AUTOSAR XML (schema 4-0-3)
package /ComponentTypes
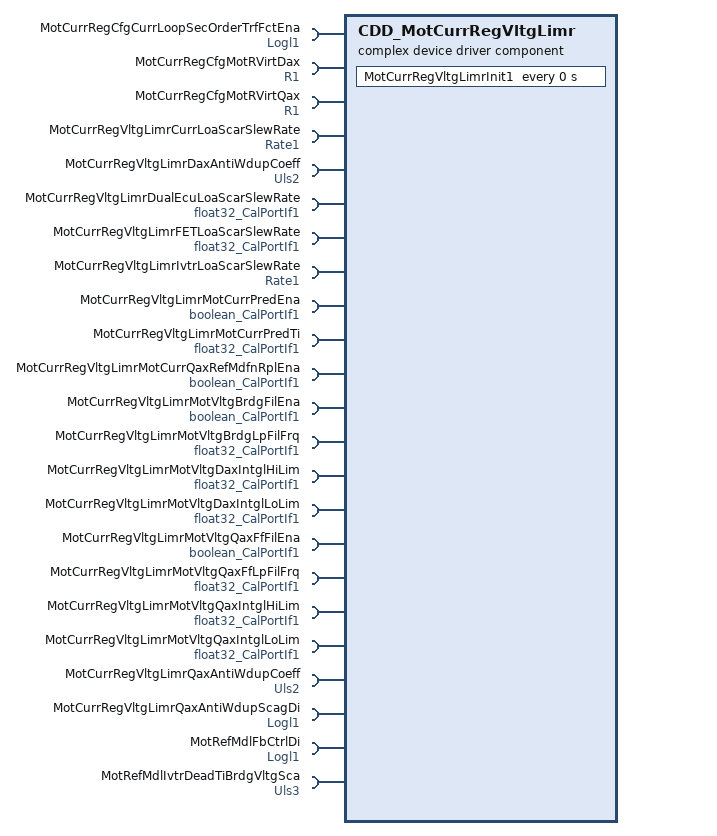
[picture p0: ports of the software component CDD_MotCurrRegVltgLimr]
  complex device driver sw component type CDD_MotCurrRegVltgLimr
    23 x require port:
      MotCurrRegCfgCurrLoopSecOrderTrfFctEna: parameter-require-com-spec{init-value=1, parameter=Logl}, required-interface=Logl1
      MotCurrRegCfgMotRVirtDax: parameter-require-com-spec{init-value=0, parameter=Val}, required-interface=R1
      MotCurrRegCfgMotRVirtQax: parameter-require-com-spec{init-value=0, parameter=Val}, required-interface=R1
      MotCurrRegVltgLimrCurrLoaScarSlewRate: parameter-require-com-spec{init-value=100, parameter=Val}, required-interface=Rate1
      MotCurrRegVltgLimrDaxAntiWdupCoeff: parameter-require-com-spec{init-value=0, parameter=Val}, required-interface=Uls2
      MotCurrRegVltgLimrDualEcuLoaScarSlewRate: parameter-require-com-spec{init-value=100, parameter=Val}, required-interface=float32_CalPortIf1
      MotCurrRegVltgLimrFETLoaScarSlewRate: parameter-require-com-spec{init-value=100, parameter=Val}, required-interface=float32_CalPortIf1
      MotCurrRegVltgLimrIvtrLoaScarSlewRate: parameter-require-com-spec{init-value=100, parameter=Val}, required-interface=Rate1
      MotCurrRegVltgLimrMotCurrPredEna: parameter-require-com-spec{init-value=0, parameter=Logl}, required-interface=boolean_CalPortIf1
      MotCurrRegVltgLimrMotCurrPredTi: parameter-require-com-spec{init-value=0, parameter=Val}, required-interface=float32_CalPortIf1
      MotCurrRegVltgLimrMotCurrQaxRefMdfnRplEna: parameter-require-com-spec{init-value=0, parameter=Logl}, required-interface=boolean_CalPortIf1
      MotCurrRegVltgLimrMotVltgBrdgFilEna: parameter-require-com-spec{init-value=1, parameter=Logl}, required-interface=boolean_CalPortIf1
      MotCurrRegVltgLimrMotVltgBrdgLpFilFrq: parameter-require-com-spec{init-value=200, parameter=Val}, required-interface=float32_CalPortIf1
      MotCurrRegVltgLimrMotVltgDaxIntglHiLim: parameter-require-com-spec{init-value=9, parameter=Val}, required-interface=float32_CalPortIf1
      MotCurrRegVltgLimrMotVltgDaxIntglLoLim: parameter-require-com-spec{init-value=-4.5, parameter=Val}, required-interface=float32_CalPortIf1
      MotCurrRegVltgLimrMotVltgQaxFfFilEna: parameter-require-com-spec{init-value=1, parameter=Logl}, required-interface=boolean_CalPortIf1
      MotCurrRegVltgLimrMotVltgQaxFfLpFilFrq: parameter-require-com-spec{init-value=500, parameter=Val}, required-interface=float32_CalPortIf1
      MotCurrRegVltgLimrMotVltgQaxIntglHiLim: parameter-require-com-spec{init-value=14.5, parameter=Val}, required-interface=float32_CalPortIf1
      MotCurrRegVltgLimrMotVltgQaxIntglLoLim: parameter-require-com-spec{init-value=-14.5, parameter=Val}, required-interface=float32_CalPortIf1
      MotCurrRegVltgLimrQaxAntiWdupCoeff: parameter-require-com-spec{init-value=0, parameter=Val}, required-interface=Uls2
      MotCurrRegVltgLimrQaxAntiWdupScagDi: parameter-require-com-spec{init-value=0, parameter=Logl}, required-interface=Logl1
      MotRefMdlFbCtrlDi: parameter-require-com-spec{init-value=0, parameter=Logl}, required-interface=Logl1
      MotRefMdlIvtrDeadTiBrdgVltgSca: parameter-require-com-spec{init-value=1, parameter=Val}, required-interface=Uls3
    behavior CDD_MotCurrRegVltgLimr_InternalBehavior: data-type-mapping=Nexteer
      ar-typed-per-instance-memorys:
        39 x data, all with sw-calibration-access=READ-ONLY:
          AntiWdupCmdScaDax: type=Uls2
          AntiWdupCmdScaQax: type=Uls2
          CurrLoaScarPrev: type=Uls2
          dMotCurrRegVltgLimrAntiWdupCmdScaDax: type=Uls2
          dMotCurrRegVltgLimrAntiWdupCmdScaQax: type=Uls2
          dMotCurrRegVltgLimrMotCurrCmdErrDax: type=Curr4
          dMotCurrRegVltgLimrMotCurrCmdErrQax: type=Curr4
          dMotCurrRegVltgLimrMotCurrCmdScaDax: type=Uls8
          dMotCurrRegVltgLimrMotCurrCmdScaQax: type=Uls8
          dMotCurrRegVltgLimrMotVltgBrdgFild: type=float32
          dMotCurrRegVltgLimrMotVltgCmdFinal: type=Volt17
          dMotCurrRegVltgLimrMotVltgCmdPreLim: type=Volt17
          dMotCurrRegVltgLimrMotVltgDampgDax: type=Volt17
          dMotCurrRegVltgLimrMotVltgDampgQax: type=Volt17
          dMotCurrRegVltgLimrMotVltgDaxFb: type=float32
          dMotCurrRegVltgLimrMotVltgDaxIntglPreLim: type=float32
          dMotCurrRegVltgLimrMotVltgDecoupldFbDax: type=Volt17
          dMotCurrRegVltgLimrMotVltgDecoupldFbQax: type=Volt17
          dMotCurrRegVltgLimrMotVltgDircFbDax: type=Volt17
          dMotCurrRegVltgLimrMotVltgDircFbQax: type=Volt17
          dMotCurrRegVltgLimrMotVltgPreLimDax: type=Volt17
          dMotCurrRegVltgLimrMotVltgPreLimQax: type=Volt17
          dMotCurrRegVltgLimrMotVltgPropCmdDax: type=Volt17
          dMotCurrRegVltgLimrMotVltgPropCmdQax: type=Volt17
          dMotCurrRegVltgLimrMotVltgQaxFb: type=float32
          dMotCurrRegVltgLimrMotVltgQaxFfFild: type=float32
          dMotCurrRegVltgLimrMotVltgQaxIntglPreLim: type=float32
          dMotCurrRegVltgLimrMotVltgSatnIvsRat: type=Uls2
          dMotCurrRegVltgLimrMotVltgSatnRat: type=Uls2
          dMotCurrRegVltgLimrPhaAdvPreDly: type=Ag10
          DualEcuLoaScarPrev: type=float32
          FETLoaScarPrev: type=float32
          IvtrLoaScarPrev: type=Uls2
          MotCtrlMotVltgDaxPrev: type=float32
          MotCtrlMotVltgQaxPrev: type=float32
          MotVltgBrdgLpFil: type=FilLpRec1
          MotVltgIntglCmdDaxPrev: type=Curr5
          MotVltgIntglCmdQaxPrev: type=Curr5
          MotVltgQaxFfLpFil: type=FilLpRec1
      timing event MotCurrRegVltgLimrInit1_InitEvent: start-on-event=MotCurrRegVltgLimrInit1, period=0
      runnable MotCurrRegVltgLimrInit1
  swc implementation CDD_MotCurrRegVltgLimr_Implementation: behavior=CDD_MotCurrRegVltgLimr_InternalBehavior
    code-descriptors:
      code Default: artifact-descriptors=autosar-engineering-object={short-label=Default, category=SWSRC}
